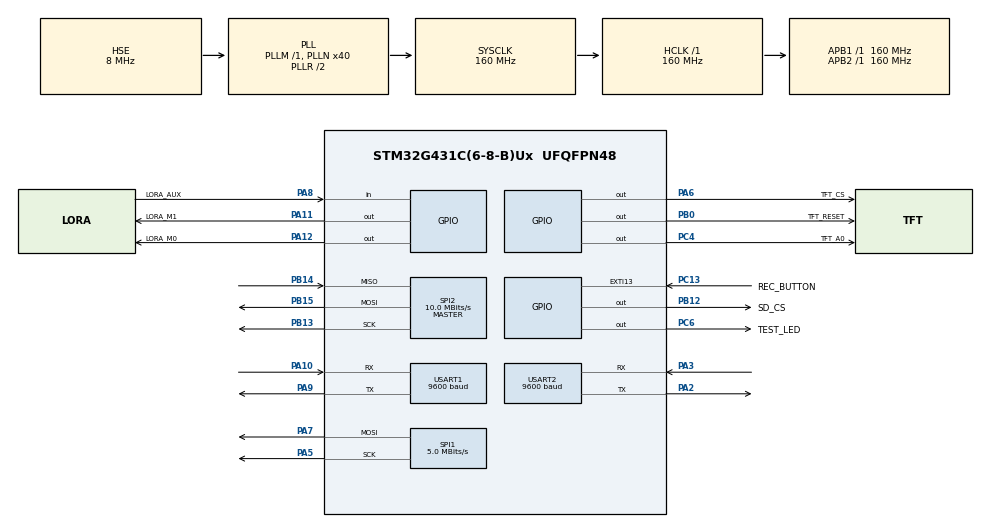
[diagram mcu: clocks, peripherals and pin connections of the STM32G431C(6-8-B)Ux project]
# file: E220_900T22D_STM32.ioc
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Dma.Request0=USART1_RX
Dma.Request1=USART1_TX
Dma.Request2=USART2_RX
Dma.Request3=USART2_TX
Dma.USART1_RX.0.Direction=DMA_PERIPH_TO_MEMORY
Dma.USART1_RX.0.EventEnable=DISABLE
Dma.USART1_RX.0.Instance=DMA1_Channel1
Dma.USART1_RX.0.MemDataAlignment=DMA_MDATAALIGN_BYTE
Dma.USART1_RX.0.MemInc=DMA_MINC_ENABLE
Dma.USART1_RX.0.Mode=DMA_CIRCULAR
Dma.USART1_RX.0.PeriphDataAlignment=DMA_PDATAALIGN_BYTE
Dma.USART1_RX.0.PeriphInc=DMA_PINC_DISABLE
Dma.USART1_RX.0.Polarity=HAL_DMAMUX_REQ_GEN_RISING
Dma.USART1_RX.0.Priority=DMA_PRIORITY_LOW
Dma.USART1_RX.0.RequestNumber=1
Dma.USART1_RX.0.SignalID=NONE
Dma.USART1_RX.0.SyncEnable=DISABLE
Dma.USART1_RX.0.SyncPolarity=HAL_DMAMUX_SYNC_NO_EVENT
Dma.USART1_RX.0.SyncRequestNumber=1
Dma.USART1_RX.0.SyncSignalID=NONE
Dma.USART1_TX.1.Direction=DMA_MEMORY_TO_PERIPH
Dma.USART1_TX.1.EventEnable=DISABLE
Dma.USART1_TX.1.Instance=DMA1_Channel2
Dma.USART1_TX.1.MemDataAlignment=DMA_MDATAALIGN_BYTE
Dma.USART1_TX.1.MemInc=DMA_MINC_ENABLE
Dma.USART1_TX.1.Mode=DMA_NORMAL
Dma.USART1_TX.1.PeriphDataAlignment=DMA_PDATAALIGN_BYTE
Dma.USART1_TX.1.PeriphInc=DMA_PINC_DISABLE
Dma.USART1_TX.1.Polarity=HAL_DMAMUX_REQ_GEN_RISING
Dma.USART1_TX.1.Priority=DMA_PRIORITY_LOW
Dma.USART1_TX.1.RequestNumber=1
Dma.USART1_TX.1.SignalID=NONE
Dma.USART1_TX.1.SyncEnable=DISABLE
Dma.USART1_TX.1.SyncPolarity=HAL_DMAMUX_SYNC_NO_EVENT
Dma.USART1_TX.1.SyncRequestNumber=1
Dma.USART1_TX.1.SyncSignalID=NONE
Dma.USART2_RX.2.Direction=DMA_PERIPH_TO_MEMORY
Dma.USART2_RX.2.EventEnable=DISABLE
Dma.USART2_RX.2.Instance=DMA1_Channel3
Dma.USART2_RX.2.MemDataAlignment=DMA_MDATAALIGN_BYTE
Dma.USART2_RX.2.MemInc=DMA_MINC_ENABLE
Dma.USART2_RX.2.Mode=DMA_CIRCULAR
Dma.USART2_RX.2.PeriphDataAlignment=DMA_PDATAALIGN_BYTE
Dma.USART2_RX.2.PeriphInc=DMA_PINC_DISABLE
Dma.USART2_RX.2.Polarity=HAL_DMAMUX_REQ_GEN_RISING
Dma.USART2_RX.2.Priority=DMA_PRIORITY_LOW
Dma.USART2_RX.2.RequestNumber=1
Dma.USART2_RX.2.SignalID=NONE
Dma.USART2_RX.2.SyncEnable=DISABLE
Dma.USART2_RX.2.SyncPolarity=HAL_DMAMUX_SYNC_NO_EVENT
Dma.USART2_RX.2.SyncRequestNumber=1
Dma.USART2_RX.2.SyncSignalID=NONE
Dma.USART2_TX.3.Direction=DMA_MEMORY_TO_PERIPH
Dma.USART2_TX.3.EventEnable=DISABLE
Dma.USART2_TX.3.Instance=DMA1_Channel4
Dma.USART2_TX.3.MemDataAlignment=DMA_MDATAALIGN_BYTE
Dma.USART2_TX.3.MemInc=DMA_MINC_ENABLE
Dma.USART2_TX.3.Mode=DMA_NORMAL
Dma.USART2_TX.3.PeriphDataAlignment=DMA_PDATAALIGN_BYTE
Dma.USART2_TX.3.PeriphInc=DMA_PINC_DISABLE
Dma.USART2_TX.3.Polarity=HAL_DMAMUX_REQ_GEN_RISING
Dma.USART2_TX.3.Priority=DMA_PRIORITY_LOW
Dma.USART2_TX.3.RequestNumber=1
Dma.USART2_TX.3.SignalID=NONE
Dma.USART2_TX.3.SyncEnable=DISABLE
Dma.USART2_TX.3.SyncPolarity=HAL_DMAMUX_SYNC_NO_EVENT
Dma.USART2_TX.3.SyncRequestNumber=1
Dma.USART2_TX.3.SyncSignalID=NONE
FATFS._MAX_SS=4096
FATFS._USE_LFN=1
Mcu.Family=STM32G4
Mcu.Name=STM32G431C(6-8-B)Ux
Mcu.Package=UFQFPN48
NVIC.DMA1_Channel1_IRQn=true\:0\:0\:false\:false\:true\:false\:true\:true
NVIC.DMA1_Channel2_IRQn=true\:0\:0\:false\:false\:true\:false\:true\:true
NVIC.DMA1_Channel3_IRQn=true\:0\:0\:false\:false\:true\:false\:true\:true
NVIC.DMA1_Channel4_IRQn=true\:0\:0\:false\:false\:true\:false\:true\:true
NVIC.EXTI15_10_IRQn=true\:0\:0\:false\:false\:true\:true\:true\:true
NVIC.PriorityGroup=NVIC_PRIORITYGROUP_4
NVIC.USART1_IRQn=true\:0\:0\:false\:false\:true\:true\:true\:true
NVIC.USART2_IRQn=true\:0\:0\:false\:false\:true\:true\:true\:true
PA10.Mode=Asynchronous
PA10.Signal=USART1_RX
PA11.GPIO_Label=LORA_M1
PA11.GPIO_Speed=GPIO_SPEED_FREQ_HIGH
PA11.Signal=GPIO_Output
PA12.GPIO_Label=LORA_M0
PA12.GPIO_Speed=GPIO_SPEED_FREQ_HIGH
PA12.Signal=GPIO_Output
PA13.Mode=Serial_Wire
PA13.Signal=SYS_JTMS-SWDIO
PA14.Mode=Serial_Wire
PA14.Signal=SYS_JTCK-SWCLK
PA2.Mode=Asynchronous
PA2.Signal=USART2_TX
PA3.Mode=Asynchronous
PA3.Signal=USART2_RX
PA5.Mode=TX_Only_Simplex_Unidirect_Master
PA5.Signal=SPI1_SCK
PA6.GPIO_Label=TFT_CS
PA6.GPIO_Speed=GPIO_SPEED_FREQ_HIGH
PA6.Signal=GPIO_Output
PA7.Mode=TX_Only_Simplex_Unidirect_Master
PA7.Signal=SPI1_MOSI
PA8.GPIO_Label=LORA_AUX
PA8.Signal=GPIO_Input
PA9.Mode=Asynchronous
PA9.Signal=USART1_TX
PB0.GPIO_Label=TFT_RESET
PB0.GPIO_Speed=GPIO_SPEED_FREQ_HIGH
PB0.Signal=GPIO_Output
PB12.GPIO_Label=SD_CS
PB12.GPIO_Speed=GPIO_SPEED_FREQ_HIGH
PB12.Signal=GPIO_Output
PB13.Mode=Full_Duplex_Master
PB13.Signal=SPI2_SCK
PB14.Mode=Full_Duplex_Master
PB14.Signal=SPI2_MISO
PB15.Mode=Full_Duplex_Master
PB15.Signal=SPI2_MOSI
PC13.GPIO_Label=REC_BUTTON
PC13.GPIO_PuPd=GPIO_PULLDOWN
PC13.Signal=GPXTI13
PC4.GPIO_Label=TFT_A0
PC4.GPIO_Speed=GPIO_SPEED_FREQ_HIGH
PC4.Signal=GPIO_Output
PC6.GPIO_Label=TEST_LED
PC6.GPIO_Speed=GPIO_SPEED_FREQ_HIGH
PC6.Signal=GPIO_Output
PF0-OSC_IN.Mode=HSE-External-Oscillator
PF0-OSC_IN.Signal=RCC_OSC_IN
PF1-OSC_OUT.Mode=HSE-External-Oscillator
PF1-OSC_OUT.Signal=RCC_OSC_OUT
ProjectManager.HeapSize=0x200
ProjectManager.StackSize=0x400
ProjectManager.TargetToolchain=STM32CubeIDE
RCC.ADC12Freq_Value=160000000
RCC.AHBFreq_Value=160000000
RCC.APB1Freq_Value=160000000
RCC.APB1TimFreq_Value=160000000
RCC.APB2Freq_Value=160000000
RCC.APB2TimFreq_Value=160000000
RCC.CK48CLockSelection=RCC_USBCLKSOURCE_HSI48
RCC.CortexFreq_Value=160000000
RCC.EXTERNAL_CLOCK_VALUE=12288000
RCC.HCLKFreq_Value=160000000
RCC.HSE_VALUE=8000000
RCC.HSI48_VALUE=48000000
RCC.HSI_VALUE=16000000
RCC.LSE_VALUE=32768
RCC.PLLN=40
RCC.PLLSourceVirtual=RCC_PLLSOURCE_HSE
RCC.SYSCLKFreq_VALUE=160000000
RCC.SYSCLKSource=RCC_SYSCLKSOURCE_PLLCLK
RCC.USBFreq_Value=48000000
RCC.VCOOutputFreq_Value=320000000
SPI1.BaudRatePrescaler=SPI_BAUDRATEPRESCALER_32
SPI1.CalculateBaudRate=5.0 MBits/s
SPI1.DataSize=SPI_DATASIZE_8BIT
SPI1.Direction=SPI_DIRECTION_2LINES
SPI1.Mode=SPI_MODE_MASTER
SPI1.VirtualType=VM_MASTER
SPI2.BaudRatePrescaler=SPI_BAUDRATEPRESCALER_16
SPI2.CalculateBaudRate=10.0 MBits/s
SPI2.DataSize=SPI_DATASIZE_8BIT
SPI2.Direction=SPI_DIRECTION_2LINES
SPI2.Mode=SPI_MODE_MASTER
SPI2.VirtualType=VM_MASTER
USART1.BaudRate=9600
USART1.OverrunDisableParam=ADVFEATURE_OVERRUN_DISABLE
USART1.VirtualMode-Asynchronous=VM_ASYNC
USART2.BaudRate=9600
USART2.VirtualMode-Asynchronous=VM_ASYNC
VP_FATFS_VS_Generic.Mode=User_defined
VP_SYS_VS_DBSignals.Mode=DisableDeadBatterySignals
board=custom

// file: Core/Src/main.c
/* USER CODE BEGIN Header */
/**
  ******************************************************************************
  * @file           : main.c
  * @brief          : Main program body
  ******************************************************************************
  * @attention
  *
  * Copyright (c) 2025 STMicroelectronics.
  * All rights reserved.
  *
  * This software is licensed under terms that can be found in the LICENSE file
  * in the root directory of this software component.
  * If no LICENSE file comes with this software, it is provided AS-IS.
  *
  ******************************************************************************
  */
/* USER CODE END Header */
#include "main.h"
#include "app_fatfs.h"

/* USER CODE BEGIN Includes */
#include "CCalls.h"
/* USER CODE END Includes */

SPI_HandleTypeDef hspi1;
SPI_HandleTypeDef hspi2;

UART_HandleTypeDef huart1;
UART_HandleTypeDef huart2;
DMA_HandleTypeDef hdma_usart1_rx;
DMA_HandleTypeDef hdma_usart1_tx;
DMA_HandleTypeDef hdma_usart2_rx;
DMA_HandleTypeDef hdma_usart2_tx;

void SystemClock_Config(void);
static void MX_GPIO_Init(void);
static void MX_DMA_Init(void);
static void MX_USART1_UART_Init(void);
static void MX_SPI1_Init(void);
static void MX_USART2_UART_Init(void);
static void MX_SPI2_Init(void);

int main(void)
{

  /* MCU Configuration--------------------------------------------------------*/

  /* Reset of all peripherals, Initializes the Flash interface and the Systick. */
  HAL_Init();

  /* USER CODE BEGIN Init */
  createMainMCU(&huart1, &hdma_usart1_rx, &hdma_usart1_tx,   // LoRa
                &huart2, &hdma_usart2_rx, &hdma_usart2_tx,   // uBLOX
                &hspi1,                                      // TFT
                &hspi2                                       // SD card
               );
  /* USER CODE END Init */

  /* Configure the system clock */
  SystemClock_Config();

  /* Initialize all configured peripherals */
  MX_GPIO_Init();
  MX_DMA_Init();
  MX_USART1_UART_Init();
  MX_SPI1_Init();
  MX_USART2_UART_Init();
  MX_SPI2_Init();
  if (MX_FATFS_Init() != APP_OK) {
    Error_Handler();
  }
  /* USER CODE BEGIN 2 */
  initMainMCU();
  /* USER CODE END 2 */

  /* Infinite loop */
  while (1)
  {

    /* USER CODE BEGIN 3 */
	  loopMainMCU();
  }
  /* USER CODE END 3 */
}

void SystemClock_Config(void)
{
  RCC_OscInitTypeDef RCC_OscInitStruct = {0};
  RCC_ClkInitTypeDef RCC_ClkInitStruct = {0};

  /** Configure the main internal regulator output voltage
  */
  HAL_PWREx_ControlVoltageScaling(PWR_REGULATOR_VOLTAGE_SCALE1_BOOST);

  /** Initializes the RCC Oscillators according to the specified parameters
  * in the RCC_OscInitTypeDef structure.
  */
  RCC_OscInitStruct.OscillatorType = RCC_OSCILLATORTYPE_HSE;
  RCC_OscInitStruct.HSEState = RCC_HSE_ON;
  RCC_OscInitStruct.PLL.PLLState = RCC_PLL_ON;
  RCC_OscInitStruct.PLL.PLLSource = RCC_PLLSOURCE_HSE;
  RCC_OscInitStruct.PLL.PLLM = RCC_PLLM_DIV1;
  RCC_OscInitStruct.PLL.PLLN = 40;
  RCC_OscInitStruct.PLL.PLLP = RCC_PLLP_DIV2;
  RCC_OscInitStruct.PLL.PLLQ = RCC_PLLQ_DIV2;
  RCC_OscInitStruct.PLL.PLLR = RCC_PLLR_DIV2;
  if (HAL_RCC_OscConfig(&RCC_OscInitStruct) != HAL_OK)
  {
    Error_Handler();
  }

  /** Initializes the CPU, AHB and APB buses clocks
  */
  RCC_ClkInitStruct.ClockType = RCC_CLOCKTYPE_HCLK|RCC_CLOCKTYPE_SYSCLK
                              |RCC_CLOCKTYPE_PCLK1|RCC_CLOCKTYPE_PCLK2;
  RCC_ClkInitStruct.SYSCLKSource = RCC_SYSCLKSOURCE_PLLCLK;
  RCC_ClkInitStruct.AHBCLKDivider = RCC_SYSCLK_DIV1;
  RCC_ClkInitStruct.APB1CLKDivider = RCC_HCLK_DIV1;
  RCC_ClkInitStruct.APB2CLKDivider = RCC_HCLK_DIV1;

  if (HAL_RCC_ClockConfig(&RCC_ClkInitStruct, FLASH_LATENCY_4) != HAL_OK)
  {
    Error_Handler();
  }
}

static void MX_SPI1_Init(void)
{

  /* SPI1 parameter configuration*/
  hspi1.Instance = SPI1;
  hspi1.Init.Mode = SPI_MODE_MASTER;
  hspi1.Init.Direction = SPI_DIRECTION_2LINES;
  hspi1.Init.DataSize = SPI_DATASIZE_8BIT;
  hspi1.Init.CLKPolarity = SPI_POLARITY_LOW;
  hspi1.Init.CLKPhase = SPI_PHASE_1EDGE;
  hspi1.Init.NSS = SPI_NSS_SOFT;
  hspi1.Init.BaudRatePrescaler = SPI_BAUDRATEPRESCALER_32;
  hspi1.Init.FirstBit = SPI_FIRSTBIT_MSB;
  hspi1.Init.TIMode = SPI_TIMODE_DISABLE;
  hspi1.Init.CRCCalculation = SPI_CRCCALCULATION_DISABLE;
  hspi1.Init.CRCPolynomial = 7;
  hspi1.Init.CRCLength = SPI_CRC_LENGTH_DATASIZE;
  hspi1.Init.NSSPMode = SPI_NSS_PULSE_ENABLE;
  if (HAL_SPI_Init(&hspi1) != HAL_OK)
  {
    Error_Handler();
  }

}

static void MX_SPI2_Init(void)
{

  /* SPI2 parameter configuration*/
  hspi2.Instance = SPI2;
  hspi2.Init.Mode = SPI_MODE_MASTER;
  hspi2.Init.Direction = SPI_DIRECTION_2LINES;
  hspi2.Init.DataSize = SPI_DATASIZE_8BIT;
  hspi2.Init.CLKPolarity = SPI_POLARITY_LOW;
  hspi2.Init.CLKPhase = SPI_PHASE_1EDGE;
  hspi2.Init.NSS = SPI_NSS_SOFT;
  hspi2.Init.BaudRatePrescaler = SPI_BAUDRATEPRESCALER_16;
  hspi2.Init.FirstBit = SPI_FIRSTBIT_MSB;
  hspi2.Init.TIMode = SPI_TIMODE_DISABLE;
  hspi2.Init.CRCCalculation = SPI_CRCCALCULATION_DISABLE;
  hspi2.Init.CRCPolynomial = 7;
  hspi2.Init.CRCLength = SPI_CRC_LENGTH_DATASIZE;
  hspi2.Init.NSSPMode = SPI_NSS_PULSE_ENABLE;
  if (HAL_SPI_Init(&hspi2) != HAL_OK)
  {
    Error_Handler();
  }

}

static void MX_USART1_UART_Init(void)
{

  huart1.Instance = USART1;
  huart1.Init.BaudRate = 9600;
  huart1.Init.WordLength = UART_WORDLENGTH_8B;
  huart1.Init.StopBits = UART_STOPBITS_1;
  huart1.Init.Parity = UART_PARITY_NONE;
  huart1.Init.Mode = UART_MODE_TX_RX;
  huart1.Init.HwFlowCtl = UART_HWCONTROL_NONE;
  huart1.Init.OverSampling = UART_OVERSAMPLING_16;
  huart1.Init.OneBitSampling = UART_ONE_BIT_SAMPLE_DISABLE;
  huart1.Init.ClockPrescaler = UART_PRESCALER_DIV1;
  huart1.AdvancedInit.AdvFeatureInit = UART_ADVFEATURE_RXOVERRUNDISABLE_INIT;
  huart1.AdvancedInit.OverrunDisable = UART_ADVFEATURE_OVERRUN_DISABLE;
  if (HAL_UART_Init(&huart1) != HAL_OK)
  {
    Error_Handler();
  }
  if (HAL_UARTEx_SetTxFifoThreshold(&huart1, UART_TXFIFO_THRESHOLD_1_8) != HAL_OK)
  {
    Error_Handler();
  }
  if (HAL_UARTEx_SetRxFifoThreshold(&huart1, UART_RXFIFO_THRESHOLD_1_8) != HAL_OK)
  {
    Error_Handler();
  }
  if (HAL_UARTEx_DisableFifoMode(&huart1) != HAL_OK)
  {
    Error_Handler();
  }

}

static void MX_USART2_UART_Init(void)
{

  huart2.Instance = USART2;
  huart2.Init.BaudRate = 9600;
  huart2.Init.WordLength = UART_WORDLENGTH_8B;
  huart2.Init.StopBits = UART_STOPBITS_1;
  huart2.Init.Parity = UART_PARITY_NONE;
  huart2.Init.Mode = UART_MODE_TX_RX;
  huart2.Init.HwFlowCtl = UART_HWCONTROL_NONE;
  huart2.Init.OverSampling = UART_OVERSAMPLING_16;
  huart2.Init.OneBitSampling = UART_ONE_BIT_SAMPLE_DISABLE;
  huart2.Init.ClockPrescaler = UART_PRESCALER_DIV1;
  huart2.AdvancedInit.AdvFeatureInit = UART_ADVFEATURE_NO_INIT;
  if (HAL_UART_Init(&huart2) != HAL_OK)
  {
    Error_Handler();
  }
  if (HAL_UARTEx_SetTxFifoThreshold(&huart2, UART_TXFIFO_THRESHOLD_1_8) != HAL_OK)
  {
    Error_Handler();
  }
  if (HAL_UARTEx_SetRxFifoThreshold(&huart2, UART_RXFIFO_THRESHOLD_1_8) != HAL_OK)
  {
    Error_Handler();
  }
  if (HAL_UARTEx_DisableFifoMode(&huart2) != HAL_OK)
  {
    Error_Handler();
  }

}

static void MX_DMA_Init(void)
{

  /* DMA controller clock enable */
  __HAL_RCC_DMAMUX1_CLK_ENABLE();
  __HAL_RCC_DMA1_CLK_ENABLE();

  /* DMA interrupt init */
  /* DMA1_Channel1_IRQn interrupt configuration */
  HAL_NVIC_SetPriority(DMA1_Channel1_IRQn, 0, 0);
  HAL_NVIC_EnableIRQ(DMA1_Channel1_IRQn);
  /* DMA1_Channel2_IRQn interrupt configuration */
  HAL_NVIC_SetPriority(DMA1_Channel2_IRQn, 0, 0);
  HAL_NVIC_EnableIRQ(DMA1_Channel2_IRQn);
  /* DMA1_Channel3_IRQn interrupt configuration */
  HAL_NVIC_SetPriority(DMA1_Channel3_IRQn, 0, 0);
  HAL_NVIC_EnableIRQ(DMA1_Channel3_IRQn);
  /* DMA1_Channel4_IRQn interrupt configuration */
  HAL_NVIC_SetPriority(DMA1_Channel4_IRQn, 0, 0);
  HAL_NVIC_EnableIRQ(DMA1_Channel4_IRQn);

}

static void MX_GPIO_Init(void)
{
  GPIO_InitTypeDef GPIO_InitStruct = {0};

  /* GPIO Ports Clock Enable */
  __HAL_RCC_GPIOC_CLK_ENABLE();
  __HAL_RCC_GPIOF_CLK_ENABLE();
  __HAL_RCC_GPIOA_CLK_ENABLE();
  __HAL_RCC_GPIOB_CLK_ENABLE();

  /*Configure GPIO pin Output Level */
  HAL_GPIO_WritePin(GPIOA, TFT_CS_Pin|LORA_M1_Pin|LORA_M0_Pin, GPIO_PIN_RESET);

  /*Configure GPIO pin Output Level */
  HAL_GPIO_WritePin(GPIOC, TFT_A0_Pin|TEST_LED_Pin, GPIO_PIN_RESET);

  /*Configure GPIO pin Output Level */
  HAL_GPIO_WritePin(GPIOB, TFT_RESET_Pin|SD_CS_Pin, GPIO_PIN_RESET);

  /*Configure GPIO pin : REC_BUTTON_Pin */
  GPIO_InitStruct.Pin = REC_BUTTON_Pin;
  GPIO_InitStruct.Mode = GPIO_MODE_IT_RISING;
  GPIO_InitStruct.Pull = GPIO_PULLDOWN;
  HAL_GPIO_Init(REC_BUTTON_GPIO_Port, &GPIO_InitStruct);

  /*Configure GPIO pins : TFT_CS_Pin LORA_M1_Pin LORA_M0_Pin */
  GPIO_InitStruct.Pin = TFT_CS_Pin|LORA_M1_Pin|LORA_M0_Pin;
  GPIO_InitStruct.Mode = GPIO_MODE_OUTPUT_PP;
  GPIO_InitStruct.Pull = GPIO_NOPULL;
  GPIO_InitStruct.Speed = GPIO_SPEED_FREQ_HIGH;
  HAL_GPIO_Init(GPIOA, &GPIO_InitStruct);

  /*Configure GPIO pins : TFT_A0_Pin TEST_LED_Pin */
  GPIO_InitStruct.Pin = TFT_A0_Pin|TEST_LED_Pin;
  GPIO_InitStruct.Mode = GPIO_MODE_OUTPUT_PP;
  GPIO_InitStruct.Pull = GPIO_NOPULL;
  GPIO_InitStruct.Speed = GPIO_SPEED_FREQ_HIGH;
  HAL_GPIO_Init(GPIOC, &GPIO_InitStruct);

  /*Configure GPIO pins : TFT_RESET_Pin SD_CS_Pin */
  GPIO_InitStruct.Pin = TFT_RESET_Pin|SD_CS_Pin;
  GPIO_InitStruct.Mode = GPIO_MODE_OUTPUT_PP;
  GPIO_InitStruct.Pull = GPIO_NOPULL;
  GPIO_InitStruct.Speed = GPIO_SPEED_FREQ_HIGH;
  HAL_GPIO_Init(GPIOB, &GPIO_InitStruct);

  /*Configure GPIO pin : LORA_AUX_Pin */
  GPIO_InitStruct.Pin = LORA_AUX_Pin;
  GPIO_InitStruct.Mode = GPIO_MODE_INPUT;
  GPIO_InitStruct.Pull = GPIO_NOPULL;
  HAL_GPIO_Init(LORA_AUX_GPIO_Port, &GPIO_InitStruct);

  /* EXTI interrupt init*/
  HAL_NVIC_SetPriority(EXTI15_10_IRQn, 0, 0);
  HAL_NVIC_EnableIRQ(EXTI15_10_IRQn);

}

void Error_Handler(void)
{
  /* USER CODE BEGIN Error_Handler_Debug */
  /* User can add his own implementation to report the HAL error return state */
  __disable_irq();
  while (1)
  {
    HAL_GPIO_WritePin(TEST_LED_GPIO_Port, TEST_LED_Pin, GPIO_PIN_SET);
    HAL_Delay(500);
    HAL_GPIO_WritePin(TEST_LED_GPIO_Port, TEST_LED_Pin, GPIO_PIN_RESET);
    HAL_Delay(500);
  }
  /* USER CODE END Error_Handler_Debug */
}
